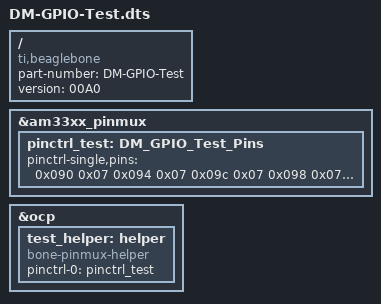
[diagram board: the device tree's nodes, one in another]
/*
* Copyright (C) 2012 Texas Instruments Incorporated - http://www.ti.com/
*
* This program is free software; you can redistribute it and/or modify
* it under the terms of the GNU General Purpose License Version 2 as
* published by the Free Software Foundation
*
* Original from: git://github.com/derekmolloy/boneDeviceTree/
*
* Modified by Nick Wernicke for the monterey beaglebone bottom side 
* controller.
*/

/dts-v1/;
/plugin/;

/{
       compatible = "ti,beaglebone", "ti,beaglebone-black";
       part-number = "DM-GPIO-Test";
       version = "00A0";

       fragment@0 {
             target = <&am33xx_pinmux>;

             __overlay__ {
                  pinctrl_test: DM_GPIO_Test_Pins {
                        pinctrl-single,pins = <

                                0x090 0x07  /* P8_07 OUTPUT MODE7 */
                                0x094 0x07  /* P8_08 OUTPUT MODE7 */
                                0x09c 0x07  /* P8_09 OUTPUT MODE7 */
                                0x098 0x07  /* P8_10 OUTPUT MODE7 */
                                0x034 0x07  /* P8_11 OUTPUT MODE7 */
				0x030 0x07  /* P8_12 OUTPUT MODE7 */
				0x028 0x07  /* P8_14 OUTPUT MODE7 */
				0x03c 0x07  /* P8_15 OUTPUT MODE7 */
				0x038 0x07  /* P8_16 OUTPUT MODE7 */
				0x02c 0x07  /* P8_17 OUTPUT MODE7 */
				0x08c 0x07  /* P8_18 OUTPUT MODE7 */ 
				0x07c 0x07  /* P8_26 OUTPUT MODE7 */
				0x0e0 0x07  /* P8_27 OUTPUT MODE7 */
				0x0e8 0x07  /* P8_28 OUTPUT MODE7 */
				0x0e4 0x07  /* P8_29 OUTPUT MODE7 */
				0x078 0x07  /* P9_12 OUTPUT MODE7 */
				0x040 0x07  /* P9_15 OUTPUT MODE7 */
				0x044 0x07  /* P9_23 OUTPUT MODE7 */
				0x1a4 0x07  /* P9_27 OUTPUT MODE7 */

                               /* OUTPUT  GPIO(mode7) 0x07 pulldown, 
0x17 pullup, 0x0f no pullup/down */
                               /* INPUT   GPIO(mode7) 0x27 pulldown, 
0x37 pullup, 0x2f no pullup/down */

                        >;
                  };
             };
       };

       fragment@1 {
                target = <&ocp>;
                __overlay__ {
                        test_helper: helper {
                                compatible = "bone-pinmux-helper";
                                pinctrl-names = "default";
                                pinctrl-0 = <&pinctrl_test>;
                                status = "okay";
                        };
                };
        };
};
